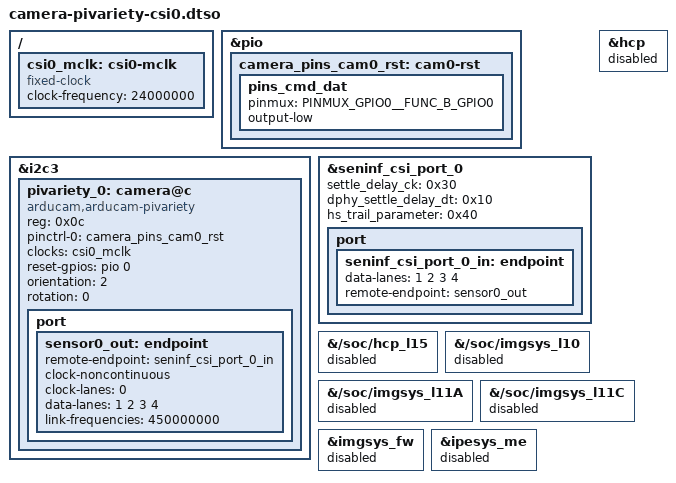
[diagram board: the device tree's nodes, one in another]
// SPDX-License-Identifier: GPL-2.0
/*
 * Copyright (c) 2024 Ezurio LLC
 *
 */

#include <dt-bindings/gpio/gpio.h>
#include <dt-bindings/pinctrl/mediatek,mt8188-pinfunc.h>

/dts-v1/;
/plugin/;

/ {
	fragment@0 {
		target-path = "/";
		__overlay__ {
			csi0_mclk: csi0-mclk {
				#clock-cells = <0>;
				clock-frequency = <24000000>;
				compatible = "fixed-clock";
			};
		};
	};

	fragment@1 {
		target = <&pio>;
		__overlay__ {
			camera_pins_cam0_rst: cam0-rst {
				pins_cmd_dat {
					pinmux = <PINMUX_GPIO0__FUNC_B_GPIO0>;
					output-low;
				};
			};
		};
	};

	fragment@2 {
		target = <&i2c3>;
		__overlay__ {
			#address-cells = <1>;
			#size-cells = <0>;

			pivariety_0: camera@c {
				compatible = "arducam,arducam-pivariety";
				reg = <0x0c>;
				pinctrl-names = "default";
				pinctrl-0 = <&camera_pins_cam0_rst>;
				clocks = <&csi0_mclk>;
				clock-names = "xclk";
				reset-gpios = <&pio 0 GPIO_ACTIVE_HIGH>;
				orientation = <2>;
				rotation = <0>;

				port {
					sensor0_out: endpoint {
						remote-endpoint = <&seninf_csi_port_0_in>;
						clock-noncontinuous;
						clock-lanes = <0>;
						data-lanes = <1 2 3 4>;
						link-frequencies = /bits/ 64 <450000000>;
					};
				};
			};
		};
	};

	fragment@3 {
		target = <&seninf_csi_port_0>;
		__overlay__ {
			status = "okay";
			settle_delay_ck = <0x30>;
			dphy_settle_delay_dt = <0x10>;
			hs_trail_parameter = <0x40>;
			port {
				seninf_csi_port_0_in: endpoint {
					data-lanes = <1 2 3 4>;
					remote-endpoint = <&sensor0_out>;
				};
			};
		};
	};

	fragment@8 {
		target = <&hcp>;
		__overlay__ {
			status = "disabled";
		};
	};

	fragment@9 {
		target-path = "/soc/hcp_l15";
		__overlay__ {
			status = "disabled";
		};
	};

	fragment@10 {
		target-path = "/soc/imgsys_l10";
		__overlay__ {
			status = "disabled";
		};
	};

	fragment@11 {
		target-path = "/soc/imgsys_l11A";
		__overlay__ {
			status = "disabled";
		};
	};

	fragment@12 {
		target-path = "/soc/imgsys_l11C";
		__overlay__ {
			status = "disabled";
		};
	};

	fragment@13 {
		target = <&imgsys_fw>;
		__overlay__ {
			status = "disabled";
		};
	};

	fragment@14 {
		target = <&ipesys_me>;
		__overlay__ {
			status = "disabled";
		};
	};
};
